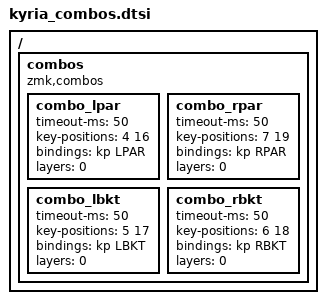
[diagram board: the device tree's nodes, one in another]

/ {
	combos {
		compatible = "zmk,combos";
		combo_lpar {
			timeout-ms = <50>;
			key-positions = <4 16>;
			bindings = <&kp LPAR>;
			layers = <0>;
		};

		combo_rpar {
			timeout-ms = <50>;
			key-positions = <7 19>;
			bindings = <&kp RPAR>;
			layers = <0>;
		};

		combo_lbkt {
			timeout-ms = <50>;
			key-positions = <5 17>;
			bindings = <&kp LBKT>;
			layers = <0>;
		};

		combo_rbkt {
			timeout-ms = <50>;
			key-positions = <6 18>;
			bindings = <&kp RBKT>;
			layers = <0>;
		};
	};
};
